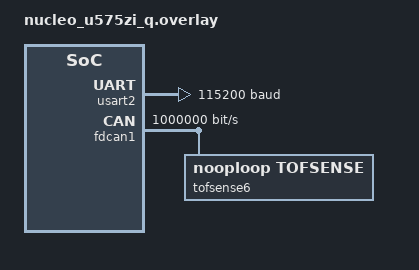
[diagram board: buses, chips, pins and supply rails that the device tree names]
/*
 * Copyright (c) 2025 Alex Fabre
 *
 * SPDX-License-Identifier: Apache-2.0
 */

#include <zephyr/dt-bindings/sensor/tofsense.h>

&usart2 {
	current-speed = <115200>;
	tofsense0 {
		compatible = "nooploop,tofsense";
		status = "disabled";
		id = <0>;
		operating-mode = <TOFSENSE_MODE_ACTIVE>;
		active-mode-frequency = <30>;
	};
};

&fdcan1 {
	bitrate = <1000000>;
	bitrate-data = <1000000>;
	tofsense6 {
		compatible = "nooploop,tofsense";
		status = "okay";
		id = <6>;
		operating-mode = <TOFSENSE_MODE_ACTIVE>;
		active-mode-frequency = <30>;
	};
};
